# R7FA4L1BD register map
Vendor: Renesas Electronics Corporation; Series: RA4; File version: 0.90.02
CPU: CM33 r0p4, little endian, MPU, FPU, VTOR, 4 interrupt priority bits, 96 interrupts
Registers are 32-bit, read-write, reset 0x0 unless marked. A register's access mark holds for its fields unless they carry their own. Offsets are from the block's base; [hi:lo] are bit positions; {n}, {i} and the like mark numbered series.

## IIC0WU — IIC0 Wake,up Unit
Base 0x4009F014
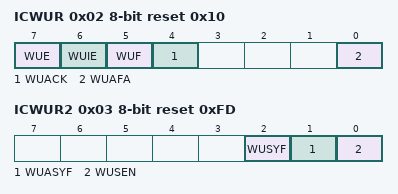
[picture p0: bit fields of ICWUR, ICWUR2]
0x02 ICWUR 8-bit reset 0x10 — I2C Bus Wakeup Unit Register
  [7] WUE — Wakeup Function Enable
  [6] WUIE — Wakeup Interrupt Request Enable
  [5] WUF — Wakeup Event Occurrence Flag
  [4] WUACK — ACK Bit for Wakeup Mode
  [0] WUAFA — Wakeup Analog Filter Additional Selection
0x03 ICWUR2 8-bit reset 0xFD — I2C Bus Wakeup Unit Register 2
  [2] WUSYF ro — Wakeup Function Synchronous Operation Status Flag
  [1] WUASYF ro — Wakeup Function Asynchronous Operation Status Flag
  [0] WUSEN — Wakeup Function Synchronous Enable

## SLCDC — Segment LCD Controller
Base 0x400D4000
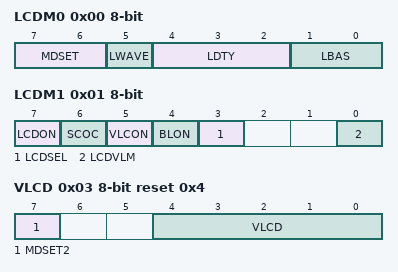
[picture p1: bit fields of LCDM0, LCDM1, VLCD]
0x00 LCDM0 8-bit — LCD Mode Register 0
  [7:6] MDSET — LCD Drive Voltage Generator Select
  [5] LWAVE — LCD Display Waveform Select
  [4:2] LDTY — Time Slice of LCD Display Select
  [1:0] LBAS — LCD Display Bias Method Select
0x01 LCDM1 8-bit — LCD Mode Register 1
  [7] LCDON — LCD Display Enable/Disable
  [6] SCOC — LCD Display Enable/Disable
  [5] VLCON — Voltage Boost Circuit or Capacitor Split Circuit Operation Enable/Disable
  [4] BLON — Alternately Display A,pattern and B,pattern Area Data (blinking display) Control
  [3] LCDSEL — Display Area Data Selection
  [0] LCDVLM — Voltage Boosting Pin Initial Value Switching Control
0x02 LCDC0 8-bit — LCD Clock Control Register 0
  [5:0] LCDC0 — LCD Clock (LCDCL) Setting
0x03 VLCD 8-bit reset 0x4 — LCD Boost Level Control Register
  [7] MDSET2 — Reference Voltage Selection
  [4:0] VLCD — Reference Voltage Select (Contrast Adjustment)
{0x100+i} SEG[{i}] (i=0..51) 8-bit — LCD Display Data Register {i}

## AGTW_B0 — Low Power Asynchronous General Purpose Timer 0
Base 0x400E8000
Same registers: AGTW_B1 0x400E8100
0x00 AGT reset 0xFFFFFFFF — AGT Counter Register
0x04 AGTCMA reset 0xFFFFFFFF — AGT CounterCompare Match A Register
0x08 AGTCMB reset 0xFFFFFFFF — AGT CounterCompare Match B Register
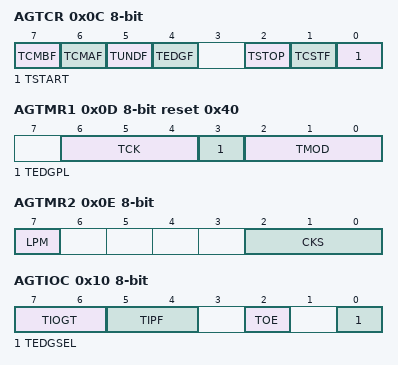
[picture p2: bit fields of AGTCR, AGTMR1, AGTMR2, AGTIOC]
0x0C AGTCR 8-bit — AGT Control Register
  [7] TCMBF — Compare Match B Flag
  [6] TCMAF — Compare Match A Flag
  [5] TUNDF — Underflow Flag
  [4] TEDGF — Active Edge Judgment Flag
  [2] TSTOP wo — AGT Count Forced Stop
  [1] TCSTF ro — AGT Count Status Flag
  [0] TSTART — AGT Count Start
0x0D AGTMR1 8-bit reset 0x40 — AGT Mode Register 1
  [6:4] TCK — Count Source
  [3] TEDGPL — Edge Polarity
  [2:0] TMOD — Operating Mode
0x0E AGTMR2 8-bit — AGT Mode Register 2
  [7] LPM — Low Power Mode
  [2:0] CKS — AGTLCLK or AGTSCLK Count Source Clock Frequency Division Ratio
0x10 AGTIOC 8-bit — AGT I/O Control Register
  [7:6] TIOGT — Count Control
  [5:4] TIPF — Input Filter
  [2] TOE — AGTOn pin Output Enable
  [0] TEDGSEL — I/O Polarity Switch
0x11 AGTISR 8-bit — AGT Event Pin Select Register
  [2] EEPS — AGTEEn Polarity Selection
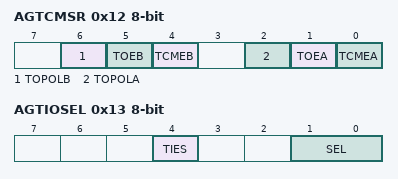
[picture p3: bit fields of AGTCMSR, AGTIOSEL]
0x12 AGTCMSR 8-bit — AGT Compare Match Function Select Register
  [6] TOPOLB — AGTOBn Pin Polarity Select
  [5] TOEB — AGTOBn Pin Output Enable
  [4] TCMEB — AGT Compare Match B Register Enable
  [2] TOPOLA — AGTOAn Pin Polarity Select
  [1] TOEA — AGTOAn Pin Output Enable
  [0] TCMEA — AGT Compare Match A Register Enable
0x13 AGTIOSEL 8-bit — AGT Pin Select Register
  [4] TIES — AGTIOn Pin Input Enable
  [1:0] SEL — AGTIOn Pin Select

## ACMPLP — Low,Power Analog Comparator
Base 0x400F4000
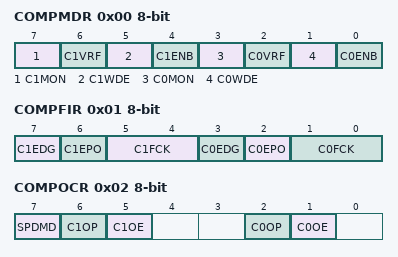
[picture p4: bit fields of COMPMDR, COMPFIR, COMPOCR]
0x00 COMPMDR 8-bit — ACMPLP Mode Setting Register
  [7] C1MON ro — ACMPLP1 Monitor Flag
  [6] C1VRF — ACMPLP1 Reference Voltage Selection
  [5] C1WDE — ACMPLP1 Window Function Mode Enable
  [4] C1ENB — ACMPLP1 Operation Enable
  [3] C0MON ro — ACMPLP0 Monitor Flag
  [2] C0VRF — ACMPLP0 Reference Voltage Selection
  [1] C0WDE — ACMPLP0 Window Function Mode Enable
  [0] C0ENB — ACMPLP0 Operation Enable
0x01 COMPFIR 8-bit — ACMPLP Filter Control Register
  [7] C1EDG — ACMPLP1 Edge Detection Selection
  [6] C1EPO — ACMPLP1 Edge Polarity Switching
  [5:4] C1FCK — ACMPLP1 Filter Select
  [3] C0EDG — ACMPLP0 Edge Detection Selection
  [2] C0EPO — ACMPLP0 Edge Polarity Switching
  [1:0] C0FCK — ACMPLP0 Filter Select
0x02 COMPOCR 8-bit — ACMPLP Output Control Register
  [7] SPDMD — ACMPLP0/ACMPLP1 Speed Selection
  [6] C1OP — ACMPLP1 VCOUT Output Polarity Selection
  [5] C1OE — ACMPLP1 VCOUT Pin Output Enable
  [2] C0OP — ACMPLP0 VCOUT Output Polarity Selection
  [1] C0OE — ACMPLP0 VCOUT Pin Output Enable
